# MSP430FR5962 register map
File version: 2.1
CPU: MSP430FR5962 r2p1, little endian, MPU, no FPU, 3 interrupt priority bits
Registers are 16-bit, read-write, reset 0x0 unless marked. A register's access mark holds for its fields unless they carry their own. Offsets are from the block's base; [hi:lo] are bit positions; {n}, {i} and the like mark numbered series.

## SFR
Base 0x00000100
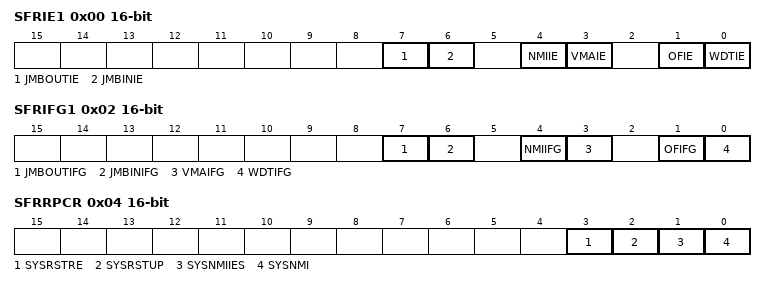
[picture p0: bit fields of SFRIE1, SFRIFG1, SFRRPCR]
0x00 SFRIE1 — Interrupt Enable
  [all] fields
    0=DISABLE (Interrupts disabled); 1=ENABLE (Interrupts enabled)
  [7] JMBOUTIE — [7:7] JTAG mailbox output interrupt enable
  [6] JMBINIE — [6:6] JTAG mailbox input interrupt enable
  [4] NMIIE — [4:4] NMI pin interrupt enable
  [3] VMAIE — [3:3] Vacant memory access interrupt enable
  [1] OFIE — [1:1] Oscillator fault interrupt enable
  [0] WDTIE — [0:0] Watchdog timer interrupt enable
0x02 SFRIFG1 — Interrupt Flag
  [7] JMBOUTIFG — [7:7] JTAG mailbox output interrupt flag
    0=No interrupt pending. When in 16-bit mode (JMBMODE = 0), this bit is cleared automatically when JMBO0 has been written with a new message to the JTAG module by the CPU. When in 32-bit mode (JMBMODE = 1), this bit is cleared automatically when both JMBO0 and JMBO1 have been written with new messages to the JTAG module by the CPU. This bit is also cleared when the associated vector in SYSUNIV has been read.; 1=Interrupt pending. JMBO registers are ready for new messages. In 16-bit mode (JMBMODE = 0), JMBO0 has been received by the JTAG module and is ready for a new message from the CPU. In 32-bit mode (JMBMODE = 1), JMBO0 and JMBO1 have been received by the JTAG module and are ready for new messages from the CPU.
  [6] JMBINIFG — [6:6] JTAG mailbox input interrupt flag
    0=No interrupt pending. When in 16-bit mode (JMBMODE = 0), this bit is cleared automatically when JMBI0 is read by the CPU. When in 32-bit mode (JMBMODE = 1), this bit is cleared automatically when both JMBI0 and JMBI1 have been read by the CPU. This bit is also cleared when the associated vector in SYSUNIV has been read; 1=Interrupt pending. A message is waiting in the JMBIN registers. In 16-bit mode (JMBMODE = 0) when JMBI0 has been written by the JTAG module. In 32-bit mode (JMBMODE = 1) when JMBI0 and JMBI1 have been written by the JTAG module.
  [4] NMIIFG — [4:4] NMI pin interrupt flag
    0=No interrupt pending; 1=Interrupt pending
  [3] VMAIFG — [3:3] Vacant memory access interrupt flag
    0=No interrupt pending; 1=Interrupt pending
  [1] OFIFG — [1:1] Oscillator fault interrupt flag
    0=No interrupt pending; 1=Interrupt pending
  [0] WDTIFG — [0:0] Watchdog timer interrupt flag
    0=No interrupt pending; 1=Interrupt pending
0x04 SFRRPCR — Reset Pin Control
  [3] SYSRSTRE — [3:3] Reset pin resistor enable
    0=DISABLE (Pullup or pulldown resistor at the RST/NMI pin is disabled); 1=ENABLE (Pullup or pulldown resistor at the RST/NMI pin is enabled)
  [2] SYSRSTUP — [2:2] Reset resistor pin pullup or pulldown
    0=PULLDOWN (Pulldown is selected); 1=PULLUP (Pullup is selected)
  [1] SYSNMIIES — [1:1] NMI edge select
    0=RISING (NMI on rising edge); 1=FALLING (NMI on falling edge)
  [0] SYSNMI — [0:0] NMI select
    0=RESET (Reset function); 1=NMI (NMI function)

## TA0
Base 0x00000340
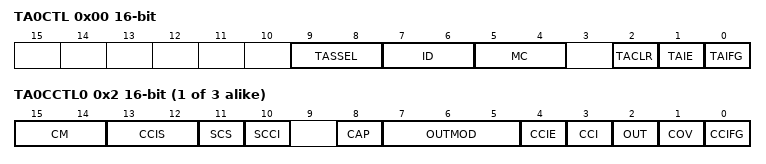
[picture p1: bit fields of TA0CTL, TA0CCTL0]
0x00 TA0CTL — TimerAx Control Register
  [9:8] TASSEL — [9:8] TimerA clock source select
    0=TACLK (TAxCLK); 1=ACLK; 2=SMCLK; 3=INCLK
  [7:6] ID — [7:6] Input divider
    0=1; 1=2; 2=4; 3=8
  [5:4] MC — [5:4] Mode control
    0=STOP (Stop mode: Timer is halted); 1=UP (Up mode: Timer counts up to TAxCCR0); 2=CONTINUOUS (Continuous mode: Timer counts up to 0FFFFh); 3=UPDOWN (Up/down mode: Timer counts up to TAxCCR0 then down to 0000h)
  [2] TACLR — [2:2] TimerA clear
  [1] TAIE — [1:1] TimerA interrupt enable
    0=Interrupt disabled; 1=Interrupt enabled
  [0] TAIFG — [0:0] TimerA interrupt flag
    0=No interrupt pending; 1=Interrupt pending
{0x2+2i} TA0CCTL{i} (i=0..2) — Timer_A Capture/Compare Control Register
  [15:14] CM — [15:14] Capture mode
    0=NONE (No capture); 1=RISING (Capture on rising edge); 2=FALLING (Capture on falling edge); 3=BOTH (Capture on both rising and falling edges)
  [13:12] CCIS — [13:12] Capture/compare input select
    0=CCIA (CCIxA); 1=CCIB (CCIxB); 2=GND; 3=VCC
  [11] SCS — [11:11] Synchronize capture source
    0=ASYNC (Asynchronous capture); 1=SYNC (Synchronous capture)
  [10] SCCI — [10:10] Synchronized capture/compare input
  [8] CAP — [8:8] Capture mode
    0=COMPARE (Compare mode); 1=CAPTURE (Capture mode)
  [7:5] OUTMOD — [7:5] Output mode
    0=OUT bit value; 1=Set; 2=Toggle/reset; 3=Set/reset; 4=Toggle; 5=Reset; 6=Toggle/set; 7=Reset/set
  [4] CCIE — [4:4] Capture/compare interrupt enable
    0=Interrupt disabled; 1=Interrupt enabled
  [3] CCI — [3:3] Capture/compare input
  [2] OUT — [2:2] Output
    0=LOW (Output low); 1=HIGH (Output high)
  [1] COV — [1:1] Capture overflow
    0=No capture overflow occurred; 1=Capture overflow occurred
  [0] CCIFG — [0:0] Capture/compare interrupt flag
    0=No interrupt pending; 1=Interrupt pending
0x10 TA0R — TimerA register
{0x12+2i} TA0CCR{i} (i=0..2) — Timer_A Capture/Compare Register
0x20 TA0EX0 — TimerAx Expansion 0 Register
  [2:0] TAIDEX — [2:0] Input divider expansion
    {v}=Divide by {v+1} (v=0..7)
0x2E TA0IV — TimerAx Interrupt Vector Register
  [15:0] TAIV — [15:0] TimerA interrupt vector value
    0=NONE (No interrupt pending); 2=TACCR1 (Interrupt Source: Capture/compare 1; Interrupt Flag: TAxCCR1 CCIFG; Interrupt Priority: Highest); 4=TACCR2 (Interrupt Source: Capture/compare 2; Interrupt Flag: TAxCCR2 CCIFG); 6=TACCR3 (Interrupt Source: Capture/compare 3; Interrupt Flag: TAxCCR3 CCIFG); 8=TACCR4 (Interrupt Source: Capture/compare 4; Interrupt Flag: TAxCCR4 CCIFG); 10=TACCR5 (Interrupt Source: Capture/compare 5; Interrupt Flag: TAxCCR5 CCIFG); 12=TACCR6 (Interrupt Source: Capture/compare 6; Interrupt Flag: TAxCCR6 CCIFG); 14=TAIFG (Interrupt Source: Timer overflow; Interrupt Flag: TAxCTL TAIFG; Interrupt Priority: Lowest)

## TA1
Base 0x00000380
Registers as TA0 (with TA0 read as TA1).

## TA2
Base 0x00000400
Registers as TA0 (with TA0 read as TA2), without TA0CCTL2, TA0CCR2.

## TA3
Base 0x00000440
Registers as TA0 (with TA0 read as TA3), without TA0CCTL2, TA0CCR2.

## TA4
Base 0x000007C0
Registers as TA0 (with TA0 read as TA4).

## WDT_A
Base 0x0000015C
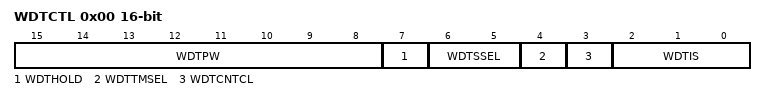
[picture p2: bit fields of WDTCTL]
0x00 WDTCTL — Watchdog Timer Control Register
  [15:8] WDTPW — [15:8] Watchdog timer password
  [7] WDTHOLD — [7:7] Watchdog timer hold
    0=UNHOLD (Watchdog timer is not stopped); 1=HOLD (Watchdog timer is stopped)
  [6:5] WDTSSEL — [6:5] Watchdog timer clock source select
    0=SMCLK; 1=ACLK; 2=VLOCLK; 3=BCLK
  [4] WDTTMSEL — [4:4] Watchdog timer mode select
    0=Watchdog mode; 1=Interval timer mode
  [3] WDTCNTCL — [3:3] Watchdog timer counter clear
    0=No action; 1=WDTCNT = 0000h
  [2:0] WDTIS — [2:0] Watchdog timer interval select
    0=2G (Watchdog clock source / (2^(31)) (18:12:16 at 32.768 kHz)); 1=128M (Watchdog clock source /(2^(27)) (01:08:16 at 32.768 kHz)); 2=8192K (Watchdog clock source /(2^(23)) (00:04:16 at 32.768 kHz)); 3=512K (Watchdog clock source /(2^(19)) (00:00:16 at 32.768 kHz)); 4=32K (Watchdog clock source /(2^(15)) (1 s at 32.768 kHz)); 5=Watchdog clock source / (2^(13)) (250 ms at 32.768 kHz); 6=Watchdog clock source / (2^(9)) (15.625 ms at 32.768 kHz); 7=Watchdog clock source / (2^(6)) (1.95 ms at 32.768 kHz)
